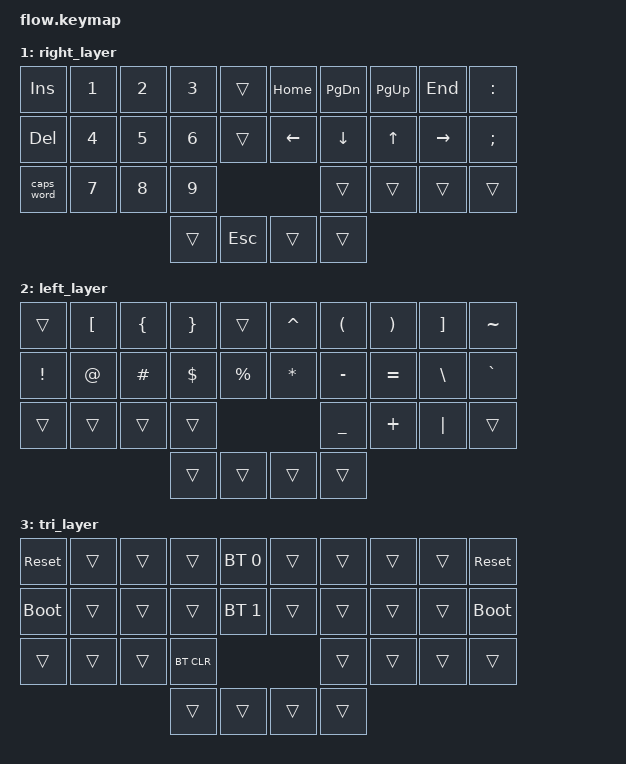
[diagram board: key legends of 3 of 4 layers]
// Copyright (c) 2022 The ZMK Contributors
// SPDX-License-Identifier: MIT

#include <behaviors.dtsi>
#include <dt-bindings/zmk/keys.h>
#include <dt-bindings/zmk/bt.h>

// Home row mods macro
#define HRML(k1,k2,k3,k4) &ht LGUI k1  &ht LALT k2  &ht LCTRL k3  &ht LSHIFT k4
#define HRMR(k1,k2,k3,k4) &ht RSHIFT k1  &ht RCTRL k2  &ht RALT k3  &ht RGUI k4

/ {
    behaviors {
        ht: hold_tap {
            compatible = "zmk,behavior-hold-tap";
            #binding-cells = <2>;
            flavor = "tap-preferred";
            tapping-term-ms = <220>;
            quick-tap-ms = <150>;
            require-prior-idle-ms = <100>;
            bindings = <&kp>, <&kp>;
        };
    };

    conditional_layers {
        compatible = "zmk,conditional-layers";
        tri_layer {
            if-layers = <1 2>;
            then-layer = <3>;
        };
    };

    keymap {
        compatible = "zmk,keymap";
        default_layer {
            bindings = <
        //╭──────────┬──────────┬──────────┬──────────┬──────────╮   ╭──────────┬──────────┬──────────┬──────────┬──────────╮
        //│  V       │  L       │  H       │  F       │  B       │   │  P       │  W       │  U       │  O       │  ,       │
            &kp V      &kp L      &kp H      &kp F      &kp B          &kp P      &kp W      &kp U      &kp O      &kp COMMA
        //├──────────┼──────────┼──────────┼──────────┼──────────┤   ├──────────┼──────────┼──────────┼──────────┼──────────┤
        //│  S       │  R       │  N       │  T       │  K       │   │  Y       │  G       │  E       │  A       │  I       │
            HRML(S,        R,         N,         T)     &kp K          &kp Y      HRMR(G,        E,         A,        I)
        //├──────────┼──────────┼──────────┼──────────┼──────────╯   ╰──────────┼──────────┼──────────┼──────────┼──────────┤
        //│  Z       │  J       │  M       │  D       │                         │  C       │  X       │ Q        │ .        │
            &kp Z      &kp J      &kp M      &kp D                                 &kp C      &kp X     &kp Q      &kp DOT
        //╰──────────┴──────────┴──────────┼──────────┼──────────╮   ╭──────────┼──────────┼──────────┴──────────┴──────────╯
                                            &lt 2 TAB   &kp Enter     &kp Space  &lt 1 BSPC
        //                                 ╰──────────┴──────────╯   ╰──────────┴──────────╯
            >;
        };

        right_layer {
            bindings = <
        //╭──────────┬──────────┬──────────┬──────────┬──────────╮   ╭──────────┬──────────┬──────────┬──────────┬──────────╮
        //│ INSERT   │  1       │  2       │  3       │          │   │ HOME     │ PAGE DN  │ PAGE UP  │ END      │  :       │
            &kp INS    &kp N1     &kp N2     &kp N3     &trans         &kp HOME   &kp PG_DN  &kp PG_UP  &kp END    &kp COLON
        //├──────────┼──────────┼──────────┼──────────┼──────────┤   ├──────────┼──────────┼──────────┼──────────┼──────────┤
        //│ DELETE   │  4       │  5       │  6       │          │   │ LEFT     │ DOWN     │ UP       │ RIGHT    │  ;       │
            &kp DEL    &kp N4     &kp N5     &kp N6     &trans         &kp LEFT   &kp DOWN   &kp UP   &kp RIGHT   &kp SEMI
        //├──────────┼──────────┼──────────┼──────────┼──────────╯   ╰──────────┼──────────┼──────────┼──────────┼──────────┤
        //│ CAPS     │  7       │  8       │  9       │                         │          │          │          │          │
           &caps_word  &kp N7     &kp N8     &kp N9                               &trans     &trans     &trans     &trans
        //╰──────────┴──────────┴──────────┼──────────┼──────────╮   ╭──────────┼──────────┼──────────┴──────────┴──────────╯
                                             &trans     &kp ESC        &trans     &trans
        //                                 ╰──────────┴──────────╯   ╰──────────┴──────────╯
            >;
        };

        left_layer {
            bindings = <
        //╭──────────┬──────────┬──────────┬──────────┬──────────╮   ╭──────────┬──────────┬──────────┬──────────┬──────────╮
        //│          │  [       │  {       │  }       │          │   │  ^       │  (       │  )       │  ]       │  ~       │
            &trans     &kp LBKT   &kp LBRC   &kp RBRC   &trans         &kp CARET  &kp LPAR   &kp RPAR   &kp RBKT   &kp TILDE
        //├──────────┼──────────┼──────────┼──────────┼──────────┤   ├──────────┼──────────┼──────────┼──────────┼──────────┤
        //│  !       │  @       │  #       │  $       │  %       │   │  *       │  -       │  =       │  \       │  `       │
            &kp EXCL   &kp AT     &kp HASH   &kp DLLR   &kp PRCNT      &kp ASTRK  &kp MINUS  &kp EQUAL  &kp BSLH   &kp GRAVE
        //├──────────┼──────────┼──────────┼──────────┼──────────╯   ╰──────────┼──────────┼──────────┼──────────┼──────────┤
        //│          │          │          │          │                         │  _       │  +       │  │       │          │
            &trans     &trans     &trans     &trans                               &kp UNDER  &kp PLUS   &kp PIPE   &trans
        //╰──────────┴──────────┴──────────┼──────────┼──────────╮   ╭──────────┼──────────┼──────────┴──────────┴──────────╯
                                             &trans     &trans         &trans     &trans
        //                                 ╰──────────┴──────────╯   ╰──────────┴──────────╯
            >;
        };

        tri_layer {
            bindings = <
        //╭──────────┬──────────┬──────────┬──────────┬──────────╮   ╭──────────┬──────────┬──────────┬──────────┬──────────╮
        //│ RESET    │          │          │          │PROFILE 0 │   │          │          │          │          │  RESET   │
           &sys_reset  &trans     &trans     &trans    &bt BT_SEL 0    &trans     &trans     &trans     &trans    &sys_reset
        //├──────────┼──────────┼──────────┼──────────┼──────────┤   ├──────────┼──────────┼──────────┼──────────┼──────────┤
        //│BOOTLOADER│          │          │          │PROFILE 1 │   │          │          │          │          │BOOTLOADER│
          &bootloader  &trans     &trans     &trans    &bt BT_SEL 1    &trans     &trans     &trans     &trans    &bootloader
        //├──────────┼──────────┼──────────┼──────────┼──────────╯   ╰──────────┼──────────┼──────────┼──────────┼──────────┤
        //│          │          │          │ CLEAR BT │                         │          │          │          │          │
            &trans     &trans     &trans    &bt BT_CLR                            &trans     &trans     &trans     &trans
        //╰──────────┴──────────┴──────────┼──────────┼──────────╮   ╭──────────┼──────────┼──────────┴──────────┴──────────╯
                                             &trans     &trans         &trans     &trans
        //                                 ╰──────────┴──────────╯   ╰──────────┴──────────╯
            >;
        };
    };
};
